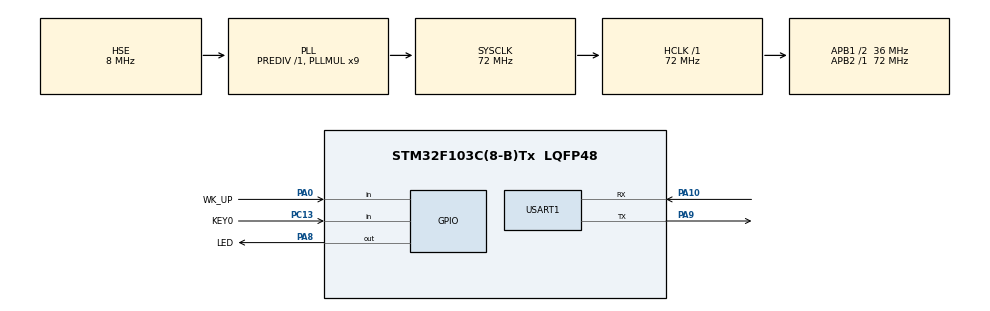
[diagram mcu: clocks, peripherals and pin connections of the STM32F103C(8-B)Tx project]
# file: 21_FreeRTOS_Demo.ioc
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FREERTOS.Tasks01=task01,24,256,mytask01,Default,NULL,Dynamic,NULL,NULL;task02,24,256,mytask02,Default,NULL,Dynamic,NULL,NULL
Mcu.Family=STM32F1
Mcu.Name=STM32F103C(8-B)Tx
Mcu.Package=LQFP48
NVIC.PriorityGroup=NVIC_PRIORITYGROUP_4
NVIC.TIM1_UP_IRQn=true\:15\:0\:false\:false\:true\:false\:false\:true\:true
NVIC.TimeBase=TIM1_UP_IRQn
NVIC.TimeBaseIP=TIM1
NVIC.USART1_IRQn=true\:5\:0\:true\:false\:true\:true\:true\:true\:true
PA0-WKUP.GPIO_Label=WK_UP
PA0-WKUP.GPIO_PuPd=GPIO_PULLDOWN
PA0-WKUP.Signal=GPIO_Input
PA10.Mode=Asynchronous
PA10.Signal=USART1_RX
PA13.Mode=Serial_Wire
PA13.Signal=SYS_JTMS-SWDIO
PA14.Mode=Serial_Wire
PA14.Signal=SYS_JTCK-SWCLK
PA8.GPIO_Label=LED
PA8.GPIO_PuPd=GPIO_PULLUP
PA8.GPIO_Speed=GPIO_SPEED_FREQ_HIGH
PA8.PinState=GPIO_PIN_SET
PA8.Signal=GPIO_Output
PA9.Mode=Asynchronous
PA9.Signal=USART1_TX
PC13-TAMPER-RTC.GPIO_Label=KEY0
PC13-TAMPER-RTC.GPIO_PuPd=GPIO_PULLUP
PC13-TAMPER-RTC.Signal=GPIO_Input
PC14-OSC32_IN.Mode=LSE-External-Oscillator
PC14-OSC32_IN.Signal=RCC_OSC32_IN
PC15-OSC32_OUT.Mode=LSE-External-Oscillator
PC15-OSC32_OUT.Signal=RCC_OSC32_OUT
PD0-OSC_IN.Mode=HSE-External-Oscillator
PD0-OSC_IN.Signal=RCC_OSC_IN
PD1-OSC_OUT.Mode=HSE-External-Oscillator
PD1-OSC_OUT.Signal=RCC_OSC_OUT
ProjectManager.HeapSize=0x200
ProjectManager.StackSize=0x400
ProjectManager.TargetToolchain=STM32CubeIDE
RCC.AHBFreq_Value=72000000
RCC.APB1CLKDivider=RCC_HCLK_DIV2
RCC.APB1Freq_Value=36000000
RCC.APB1TimFreq_Value=72000000
RCC.APB2Freq_Value=72000000
RCC.APB2TimFreq_Value=72000000
RCC.HCLKFreq_Value=72000000
RCC.PLLMUL=RCC_PLL_MUL9
RCC.PLLSourceVirtual=RCC_PLLSOURCE_HSE
RCC.SYSCLKFreq_VALUE=72000000
RCC.SYSCLKSource=RCC_SYSCLKSOURCE_PLLCLK
RCC.USBFreq_Value=72000000
USART1.VirtualMode=VM_ASYNC
VP_FREERTOS_VS_CMSIS_V2.Mode=CMSIS_V2
VP_SYS_VS_tim1.Mode=TIM1
board=custom

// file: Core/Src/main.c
/**
 ****************************************************************************************************
 * @file        main.c
 * @author      ALIENTEK
 * @brief       FreeRTOS code
 * @license     Copyright (C) 2020-2032, ALIENTEK
 ****************************************************************************************************
 * @attention
 *
 * platform  	: ALIENTEK STM32F103 development board
 * website		: https://www.alientek.com
 * forum		: http://www.openedv.com/forum.php
 *
 * change logs	:
 * version		data		notes
 * V1.0			20240222	the first version
 *
 ****************************************************************************************************
 */

/* USER CODE BEGIN Header */

/* USER CODE END Header */
#include "main.h"
#include "cmsis_os.h"
#include "usart.h"
#include "gpio.h"

/* USER CODE BEGIN Includes */
#include "../../BSP/LED/led.h"
#include "../../BSP/KEY/key.h"
/* USER CODE END Includes */

void SystemClock_Config(void);
void MX_FREERTOS_Init(void);

int main(void)
{

  /* MCU Configuration--------------------------------------------------------*/

  /* Reset of all peripherals, Initializes the Flash interface and the Systick. */
  HAL_Init();

  /* Configure the system clock */
  SystemClock_Config();

  /* Initialize all configured peripherals */
  MX_GPIO_Init();
  MX_USART1_UART_Init();

  /* Init scheduler */
  osKernelInitialize();

  /* Call init function for freertos objects (in freertos.c) */
  MX_FREERTOS_Init();

  /* Start scheduler */
  osKernelStart();

  /* We should never get here as control is now taken by the scheduler */
  /* Infinite loop */

}

void SystemClock_Config(void)
{
  RCC_OscInitTypeDef RCC_OscInitStruct = {0};
  RCC_ClkInitTypeDef RCC_ClkInitStruct = {0};

  /** Initializes the RCC Oscillators according to the specified parameters
  * in the RCC_OscInitTypeDef structure.
  */
  RCC_OscInitStruct.OscillatorType = RCC_OSCILLATORTYPE_HSE;
  RCC_OscInitStruct.HSEState = RCC_HSE_ON;
  RCC_OscInitStruct.HSEPredivValue = RCC_HSE_PREDIV_DIV1;
  RCC_OscInitStruct.HSIState = RCC_HSI_ON;
  RCC_OscInitStruct.PLL.PLLState = RCC_PLL_ON;
  RCC_OscInitStruct.PLL.PLLSource = RCC_PLLSOURCE_HSE;
  RCC_OscInitStruct.PLL.PLLMUL = RCC_PLL_MUL9;
  if (HAL_RCC_OscConfig(&RCC_OscInitStruct) != HAL_OK)
  {
    Error_Handler();
  }

  /** Initializes the CPU, AHB and APB buses clocks
  */
  RCC_ClkInitStruct.ClockType = RCC_CLOCKTYPE_HCLK|RCC_CLOCKTYPE_SYSCLK
                              |RCC_CLOCKTYPE_PCLK1|RCC_CLOCKTYPE_PCLK2;
  RCC_ClkInitStruct.SYSCLKSource = RCC_SYSCLKSOURCE_PLLCLK;
  RCC_ClkInitStruct.AHBCLKDivider = RCC_SYSCLK_DIV1;
  RCC_ClkInitStruct.APB1CLKDivider = RCC_HCLK_DIV2;
  RCC_ClkInitStruct.APB2CLKDivider = RCC_HCLK_DIV1;

  if (HAL_RCC_ClockConfig(&RCC_ClkInitStruct, FLASH_LATENCY_2) != HAL_OK)
  {
    Error_Handler();
  }
}

void HAL_TIM_PeriodElapsedCallback(TIM_HandleTypeDef *htim)
{
  if (htim->Instance == TIM1) {
    HAL_IncTick();
  }
}

void Error_Handler(void)
{
  __disable_irq();
  while (1)
  {
  }
}

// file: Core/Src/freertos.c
/* USER CODE BEGIN Header */
/**
  ******************************************************************************
  * File Name          : freertos.c
  * Description        : Code for freertos applications
  ******************************************************************************
  * @attention
  *
  * Copyright (c) 2024 STMicroelectronics.
  * All rights reserved.
  *
  * This software is licensed under terms that can be found in the LICENSE file
  * in the root directory of this software component.
  * If no LICENSE file comes with this software, it is provided AS-IS.
  *
  ******************************************************************************
  */
/* USER CODE END Header */

#include "FreeRTOS.h"
#include "task.h"
#include "main.h"
#include "cmsis_os.h"

/* USER CODE BEGIN Includes */

#include "../../BSP/LED/led.h"
#include "usart.h"

/* USER CODE END Includes */

/* Definitions for task01 */
osThreadId_t task01Handle;
const osThreadAttr_t task01_attributes = {
  .name = "task01",
  .stack_size = 256 * 4,
  .priority = (osPriority_t) osPriorityNormal,
};
/* Definitions for task02 */
osThreadId_t task02Handle;
const osThreadAttr_t task02_attributes = {
  .name = "task02",
  .stack_size = 256 * 4,
  .priority = (osPriority_t) osPriorityNormal,
};

void mytask01(void *argument);
void mytask02(void *argument);

void MX_FREERTOS_Init(void); /* (MISRA C 2004 rule 8.1) */

void MX_FREERTOS_Init(void) {

  /* Create the thread(s) */
  /* creation of task01 */
  task01Handle = osThreadNew(mytask01, NULL, &task01_attributes);

  /* creation of task02 */
  task02Handle = osThreadNew(mytask02, NULL, &task02_attributes);

}

void mytask01(void *argument)
{
  /* USER CODE BEGIN mytask01 */
  /* Infinite loop */
	while(1)
	{
		LED_TOGGLE();
		vTaskDelay(1000);
	}
  /* USER CODE END mytask01 */
}

void mytask02(void *argument)
{
  /* USER CODE BEGIN mytask02 */
  /* Infinite loop */
    while(1)
    {
        printf("STM32F103C8T6 Runing .....\r\n");
        vTaskDelay(1000);
    }
  /* USER CODE END mytask02 */
}
